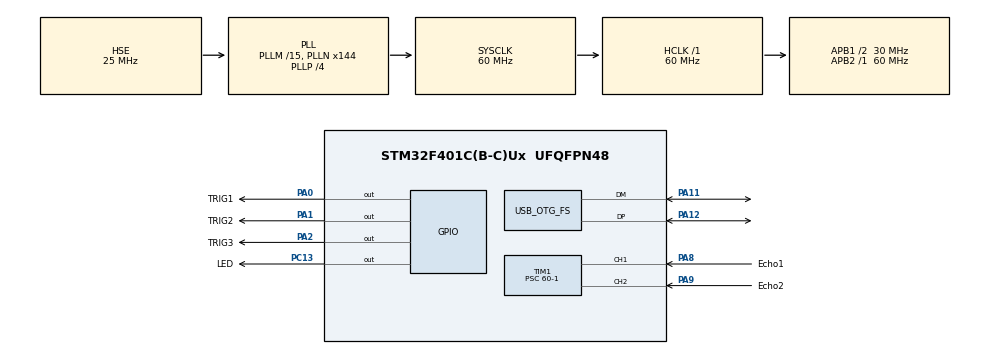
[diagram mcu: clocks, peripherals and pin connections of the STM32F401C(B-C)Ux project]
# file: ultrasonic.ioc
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Mcu.Family=STM32F4
Mcu.Name=STM32F401C(B-C)Ux
Mcu.Package=UFQFPN48
NVIC.OTG_FS_IRQn=true\:0\:0\:false\:false\:true\:false\:true\:true
NVIC.PriorityGroup=NVIC_PRIORITYGROUP_4
NVIC.TIM1_CC_IRQn=true\:0\:0\:false\:false\:true\:true\:true\:true
PA0-WKUP.GPIO_Label=TRIG1
PA0-WKUP.GPIO_PuPd=GPIO_PULLDOWN
PA0-WKUP.Signal=GPIO_Output
PA1.GPIO_Label=TRIG2
PA1.GPIO_PuPd=GPIO_PULLDOWN
PA1.Signal=GPIO_Output
PA10.GPIO_Label=Echo3
PA10.GPIO_PuPd=GPIO_PULLDOWN
PA10.Signal=S_TIM1_CH3
PA11.Mode=Device_Only
PA11.Signal=USB_OTG_FS_DM
PA12.Mode=Device_Only
PA12.Signal=USB_OTG_FS_DP
PA13.Mode=Serial_Wire
PA13.Signal=SYS_JTMS-SWDIO
PA14.Mode=Serial_Wire
PA14.Signal=SYS_JTCK-SWCLK
PA2.GPIO_Label=TRIG3
PA2.GPIO_PuPd=GPIO_PULLDOWN
PA2.Signal=GPIO_Output
PA8.GPIO_Label=Echo1
PA8.GPIO_PuPd=GPIO_PULLDOWN
PA8.Signal=S_TIM1_CH1
PA9.GPIO_Label=Echo2
PA9.GPIO_PuPd=GPIO_PULLDOWN
PA9.Signal=S_TIM1_CH2
PC13-ANTI_TAMP.GPIO_Label=LED
PC13-ANTI_TAMP.GPIO_PuPd=GPIO_PULLDOWN
PC13-ANTI_TAMP.Signal=GPIO_Output
PH0\ -\ OSC_IN.Mode=HSE-External-Oscillator
PH0\ -\ OSC_IN.Signal=RCC_OSC_IN
PH1\ -\ OSC_OUT.Mode=HSE-External-Oscillator
PH1\ -\ OSC_OUT.Signal=RCC_OSC_OUT
ProjectManager.HeapSize=0x200
ProjectManager.StackSize=0x400
ProjectManager.TargetToolchain=STM32CubeIDE
RCC.48MHZClocksFreq_Value=48000000
RCC.AHBFreq_Value=60000000
RCC.APB1CLKDivider=RCC_HCLK_DIV2
RCC.APB1Freq_Value=30000000
RCC.APB1TimFreq_Value=60000000
RCC.APB2Freq_Value=60000000
RCC.APB2TimFreq_Value=60000000
RCC.CortexFreq_Value=60000000
RCC.HCLKFreq_Value=60000000
RCC.HSE_VALUE=25000000
RCC.HSI_VALUE=16000000
RCC.LSE_VALUE=32768
RCC.PLLM=15
RCC.PLLN=144
RCC.PLLP=RCC_PLLP_DIV4
RCC.PLLQ=5
RCC.SYSCLKFreq_VALUE=60000000
RCC.SYSCLKSource=RCC_SYSCLKSOURCE_PLLCLK
RCC.VCOOutputFreq_Value=240000000
SH.S_TIM1_CH1.0=TIM1_CH1,Input_Capture1_from_TI1
SH.S_TIM1_CH2.0=TIM1_CH2
SH.S_TIM1_CH2.1=TIM1_CH2,TriggerSource_TI2FP2
SH.S_TIM1_CH3.0=TIM1_CH3
TIM1.AutoReloadPreload=TIM_AUTORELOAD_PRELOAD_ENABLE
TIM1.Channel-Input_Capture1_from_TI1=TIM_CHANNEL_1
TIM1.ICPolarity_CH1=TIM_INPUTCHANNELPOLARITY_RISING
TIM1.Period=65536-1
TIM1.Prescaler=60-1
TIM2.AutoReloadPreload=TIM_AUTORELOAD_PRELOAD_ENABLE
TIM2.Period=65535
TIM2.Prescaler=60-1
USB_DEVICE.CLASS_NAME_FS=CDC
USB_DEVICE.VirtualMode=Cdc
USB_DEVICE.VirtualModeFS=Cdc_FS
USB_OTG_FS.VirtualMode=Device_Only
VP_TIM1_VS_ClockSourceINT.Mode=Internal
VP_TIM1_VS_ControllerModeReset.Mode=Reset Mode
VP_TIM2_VS_ClockSourceINT.Mode=Internal
VP_USB_DEVICE_VS_USB_DEVICE_CDC_FS.Mode=CDC_FS
board=custom

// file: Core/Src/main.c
/* USER CODE BEGIN Header */
/**
  ******************************************************************************
  * @file           : main.c
  * @brief          : Main program body
  ******************************************************************************
  * @attention
  *
  * Copyright (c) 2024 STMicroelectronics.
  * All rights reserved.
  *
  * This software is licensed under terms that can be found in the LICENSE file
  * in the root directory of this software component.
  * If no LICENSE file comes with this software, it is provided AS-IS.
  *
  ******************************************************************************
  */
/* USER CODE END Header */
#include "main.h"
#include "usb_device.h"

/* USER CODE BEGIN Includes */
#include "usbd_cdc_if.h"
#include "hcSR04.h"
#include "stdio.h"

/* USER CODE END Includes */

TIM_HandleTypeDef htim1;
TIM_HandleTypeDef htim2;

void SystemClock_Config(void);
static void MX_GPIO_Init(void);
static void MX_TIM1_Init(void);
static void MX_TIM2_Init(void);

/* USER CODE BEGIN 0 */

// Let's write the callback function

/* USER CODE END 0 */

int main(void)
{

  /* MCU Configuration--------------------------------------------------------*/

  /* Reset of all peripherals, Initializes the Flash interface and the Systick. */
  HAL_Init();

  /* Configure the system clock */
  SystemClock_Config();

  /* Initialize all configured peripherals */
  MX_GPIO_Init();
  MX_TIM1_Init();
  MX_USB_DEVICE_Init();
  MX_TIM2_Init();
  /* USER CODE BEGIN 2 */
  HAL_TIM_IC_Start_IT(&htim1 ,TIM_CHANNEL_1);
  HAL_TIM_IC_Start_IT(&htim1 ,TIM_CHANNEL_2);
  HAL_TIM_IC_Start_IT(&htim1 ,TIM_CHANNEL_3);
  HAL_TIM_Base_Start(&htim2);
  /* USER CODE END 2 */

  /* Infinite loop */
  while (1)
  {

    /* USER CODE BEGIN 3 */
	  HCSR04_Trigger();
	  HAL_Delay(1000);
  }
  /* USER CODE END 3 */
}

void SystemClock_Config(void)
{
  RCC_OscInitTypeDef RCC_OscInitStruct = {0};
  RCC_ClkInitTypeDef RCC_ClkInitStruct = {0};

  /** Configure the main internal regulator output voltage
  */
  __HAL_RCC_PWR_CLK_ENABLE();
  __HAL_PWR_VOLTAGESCALING_CONFIG(PWR_REGULATOR_VOLTAGE_SCALE2);

  /** Initializes the RCC Oscillators according to the specified parameters
  * in the RCC_OscInitTypeDef structure.
  */
  RCC_OscInitStruct.OscillatorType = RCC_OSCILLATORTYPE_HSE;
  RCC_OscInitStruct.HSEState = RCC_HSE_ON;
  RCC_OscInitStruct.PLL.PLLState = RCC_PLL_ON;
  RCC_OscInitStruct.PLL.PLLSource = RCC_PLLSOURCE_HSE;
  RCC_OscInitStruct.PLL.PLLM = 15;
  RCC_OscInitStruct.PLL.PLLN = 144;
  RCC_OscInitStruct.PLL.PLLP = RCC_PLLP_DIV4;
  RCC_OscInitStruct.PLL.PLLQ = 5;
  if (HAL_RCC_OscConfig(&RCC_OscInitStruct) != HAL_OK)
  {
    Error_Handler();
  }

  /** Initializes the CPU, AHB and APB buses clocks
  */
  RCC_ClkInitStruct.ClockType = RCC_CLOCKTYPE_HCLK|RCC_CLOCKTYPE_SYSCLK
                              |RCC_CLOCKTYPE_PCLK1|RCC_CLOCKTYPE_PCLK2;
  RCC_ClkInitStruct.SYSCLKSource = RCC_SYSCLKSOURCE_PLLCLK;
  RCC_ClkInitStruct.AHBCLKDivider = RCC_SYSCLK_DIV1;
  RCC_ClkInitStruct.APB1CLKDivider = RCC_HCLK_DIV2;
  RCC_ClkInitStruct.APB2CLKDivider = RCC_HCLK_DIV1;

  if (HAL_RCC_ClockConfig(&RCC_ClkInitStruct, FLASH_LATENCY_1) != HAL_OK)
  {
    Error_Handler();
  }
}

static void MX_TIM1_Init(void)
{

  TIM_ClockConfigTypeDef sClockSourceConfig = {0};
  TIM_SlaveConfigTypeDef sSlaveConfig = {0};
  TIM_MasterConfigTypeDef sMasterConfig = {0};
  TIM_IC_InitTypeDef sConfigIC = {0};

  htim1.Instance = TIM1;
  htim1.Init.Prescaler = 60-1;
  htim1.Init.CounterMode = TIM_COUNTERMODE_UP;
  htim1.Init.Period = 65536-1;
  htim1.Init.ClockDivision = TIM_CLOCKDIVISION_DIV1;
  htim1.Init.RepetitionCounter = 0;
  htim1.Init.AutoReloadPreload = TIM_AUTORELOAD_PRELOAD_ENABLE;
  if (HAL_TIM_Base_Init(&htim1) != HAL_OK)
  {
    Error_Handler();
  }
  sClockSourceConfig.ClockSource = TIM_CLOCKSOURCE_INTERNAL;
  if (HAL_TIM_ConfigClockSource(&htim1, &sClockSourceConfig) != HAL_OK)
  {
    Error_Handler();
  }
  if (HAL_TIM_IC_Init(&htim1) != HAL_OK)
  {
    Error_Handler();
  }
  sSlaveConfig.SlaveMode = TIM_SLAVEMODE_RESET;
  sSlaveConfig.InputTrigger = TIM_TS_TI2FP2;
  sSlaveConfig.TriggerPolarity = TIM_INPUTCHANNELPOLARITY_BOTHEDGE;
  sSlaveConfig.TriggerFilter = 0;
  if (HAL_TIM_SlaveConfigSynchro(&htim1, &sSlaveConfig) != HAL_OK)
  {
    Error_Handler();
  }
  sMasterConfig.MasterOutputTrigger = TIM_TRGO_RESET;
  sMasterConfig.MasterSlaveMode = TIM_MASTERSLAVEMODE_DISABLE;
  if (HAL_TIMEx_MasterConfigSynchronization(&htim1, &sMasterConfig) != HAL_OK)
  {
    Error_Handler();
  }
  sConfigIC.ICPolarity = TIM_INPUTCHANNELPOLARITY_BOTHEDGE;
  sConfigIC.ICSelection = TIM_ICSELECTION_DIRECTTI;
  sConfigIC.ICPrescaler = TIM_ICPSC_DIV1;
  sConfigIC.ICFilter = 0;
  if (HAL_TIM_IC_ConfigChannel(&htim1, &sConfigIC, TIM_CHANNEL_1) != HAL_OK)
  {
    Error_Handler();
  }
  if (HAL_TIM_IC_ConfigChannel(&htim1, &sConfigIC, TIM_CHANNEL_2) != HAL_OK)
  {
    Error_Handler();
  }
  if (HAL_TIM_IC_ConfigChannel(&htim1, &sConfigIC, TIM_CHANNEL_3) != HAL_OK)
  {
    Error_Handler();
  }

}

static void MX_TIM2_Init(void)
{

  TIM_ClockConfigTypeDef sClockSourceConfig = {0};
  TIM_MasterConfigTypeDef sMasterConfig = {0};

  htim2.Instance = TIM2;
  htim2.Init.Prescaler = 60-1;
  htim2.Init.CounterMode = TIM_COUNTERMODE_UP;
  htim2.Init.Period = 65535;
  htim2.Init.ClockDivision = TIM_CLOCKDIVISION_DIV1;
  htim2.Init.AutoReloadPreload = TIM_AUTORELOAD_PRELOAD_ENABLE;
  if (HAL_TIM_Base_Init(&htim2) != HAL_OK)
  {
    Error_Handler();
  }
  sClockSourceConfig.ClockSource = TIM_CLOCKSOURCE_INTERNAL;
  if (HAL_TIM_ConfigClockSource(&htim2, &sClockSourceConfig) != HAL_OK)
  {
    Error_Handler();
  }
  sMasterConfig.MasterOutputTrigger = TIM_TRGO_RESET;
  sMasterConfig.MasterSlaveMode = TIM_MASTERSLAVEMODE_DISABLE;
  if (HAL_TIMEx_MasterConfigSynchronization(&htim2, &sMasterConfig) != HAL_OK)
  {
    Error_Handler();
  }

}

static void MX_GPIO_Init(void)
{
  GPIO_InitTypeDef GPIO_InitStruct = {0};

  /* GPIO Ports Clock Enable */
  __HAL_RCC_GPIOC_CLK_ENABLE();
  __HAL_RCC_GPIOH_CLK_ENABLE();
  __HAL_RCC_GPIOA_CLK_ENABLE();

  /*Configure GPIO pin Output Level */
  HAL_GPIO_WritePin(LED_GPIO_Port, LED_Pin, GPIO_PIN_RESET);

  /*Configure GPIO pin Output Level */
  HAL_GPIO_WritePin(GPIOA, TRIG1_Pin|TRIG2_Pin|TRIG3_Pin, GPIO_PIN_RESET);

  /*Configure GPIO pin : LED_Pin */
  GPIO_InitStruct.Pin = LED_Pin;
  GPIO_InitStruct.Mode = GPIO_MODE_OUTPUT_PP;
  GPIO_InitStruct.Pull = GPIO_PULLDOWN;
  GPIO_InitStruct.Speed = GPIO_SPEED_FREQ_LOW;
  HAL_GPIO_Init(LED_GPIO_Port, &GPIO_InitStruct);

  /*Configure GPIO pins : TRIG1_Pin TRIG2_Pin TRIG3_Pin */
  GPIO_InitStruct.Pin = TRIG1_Pin|TRIG2_Pin|TRIG3_Pin;
  GPIO_InitStruct.Mode = GPIO_MODE_OUTPUT_PP;
  GPIO_InitStruct.Pull = GPIO_PULLDOWN;
  GPIO_InitStruct.Speed = GPIO_SPEED_FREQ_LOW;
  HAL_GPIO_Init(GPIOA, &GPIO_InitStruct);

}

void Error_Handler(void)
{
  __disable_irq();
  while (1)
  {
  }
}
